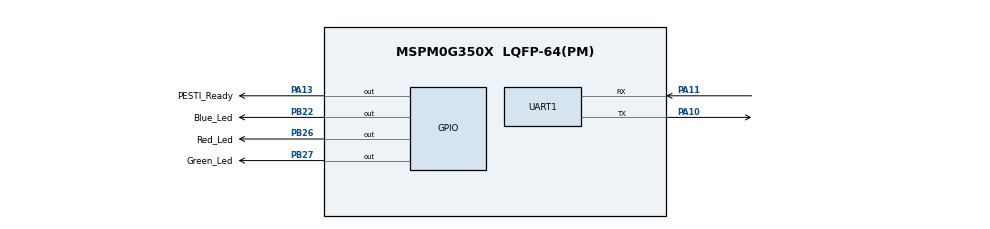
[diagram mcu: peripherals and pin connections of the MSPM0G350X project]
/**
 * @cliArgs --device "MSPM0G350X" --part "Default" --package "LQFP-64(PM)" --product "mspm0_sdk@2.02.00.06"
 * @versions {"tool":"1.21.0+3721"}
 */
// @cliArgs --board /ti/boards/LP_MSPM0G3507 --rtos nortos

/**
 * Import the modules used in this configuration.
 */
const GPIO          = scripting.addModule("/ti/driverlib/GPIO", {}, false);
const GPIO1         = GPIO.addInstance();
const GPIO2         = GPIO.addInstance();
const SYSCTL        = scripting.addModule("/ti/driverlib/SYSCTL");
const UART          = scripting.addModule("/ti/driverlib/UART", {}, false);
const UART1         = UART.addInstance();
const ProjectConfig = scripting.addModule("/ti/project_config/ProjectConfig");

/**
 * Write custom configuration values to the imported modules.
 */
GPIO1.$name                         = "GPIO_LED";
GPIO1.associatedPins.create(3);
GPIO1.associatedPins[0].$name       = "Red_Led";
GPIO1.associatedPins[0].pin.$assign = "PB26";
GPIO1.associatedPins[1].$name       = "Green_Led";
GPIO1.associatedPins[1].pin.$assign = "PB27";
GPIO1.associatedPins[2].$name       = "Blue_Led";
GPIO1.associatedPins[2].pin.$assign = "PB22";

const Board = scripting.addModule("/ti/driverlib/Board", {}, false);

GPIO2.$name                              = "GPIO_PESTI_Ready";
GPIO2.associatedPins[0].$name            = "PESTI_Ready";
GPIO2.associatedPins[0].initialValue     = "SET";
GPIO2.associatedPins[0].internalResistor = "PULL_UP";
GPIO2.associatedPins[0].pin.$assign      = "PA13";

SYSCTL.forceDefaultClkConfig = true;

UART1.$name                    = "UART_0";
UART1.enableFIFO               = true;
UART1.txFifoThreshold          = "DL_UART_TX_FIFO_LEVEL_3_4_EMPTY";
UART1.targetBaudRate           = 250000;
UART1.parity                   = "ODD";
UART1.rxFifoThreshold          = "DL_UART_RX_FIFO_LEVEL_ONE_ENTRY";
UART1.enabledInterrupts        = ["BREAK_ERROR","OVERRUN_ERROR","RX","RX_TIMEOUT_ERROR","TX"];
UART1.rxTimeoutValue           = 15;
UART1.peripheral.rxPin.$assign = "PA11";
UART1.peripheral.txPin.$assign = "PA10";
UART1.txPinConfig.$name        = "ti_driverlib_gpio_GPIOPinGeneric0";
UART1.txPinConfig.enableConfig = true;
UART1.txPinConfig.hiZ          = "ENABLE";
UART1.rxPinConfig.$name        = "ti_driverlib_gpio_GPIOPinGeneric1";

/**
 * Pinmux solution for unlocked pins/peripherals. This ensures that minor changes to the automatic solver in a future
 * version of the tool will not impact the pinmux you originally saw.  These lines can be completely deleted in order to
 * re-solve from scratch.
 */
Board.peripheral.$suggestSolution          = "DEBUGSS";
Board.peripheral.swclkPin.$suggestSolution = "PA20";
Board.peripheral.swdioPin.$suggestSolution = "PA19";
SYSCTL.peripheral.$suggestSolution         = "SYSCTL";
UART1.peripheral.$suggestSolution          = "UART0";
